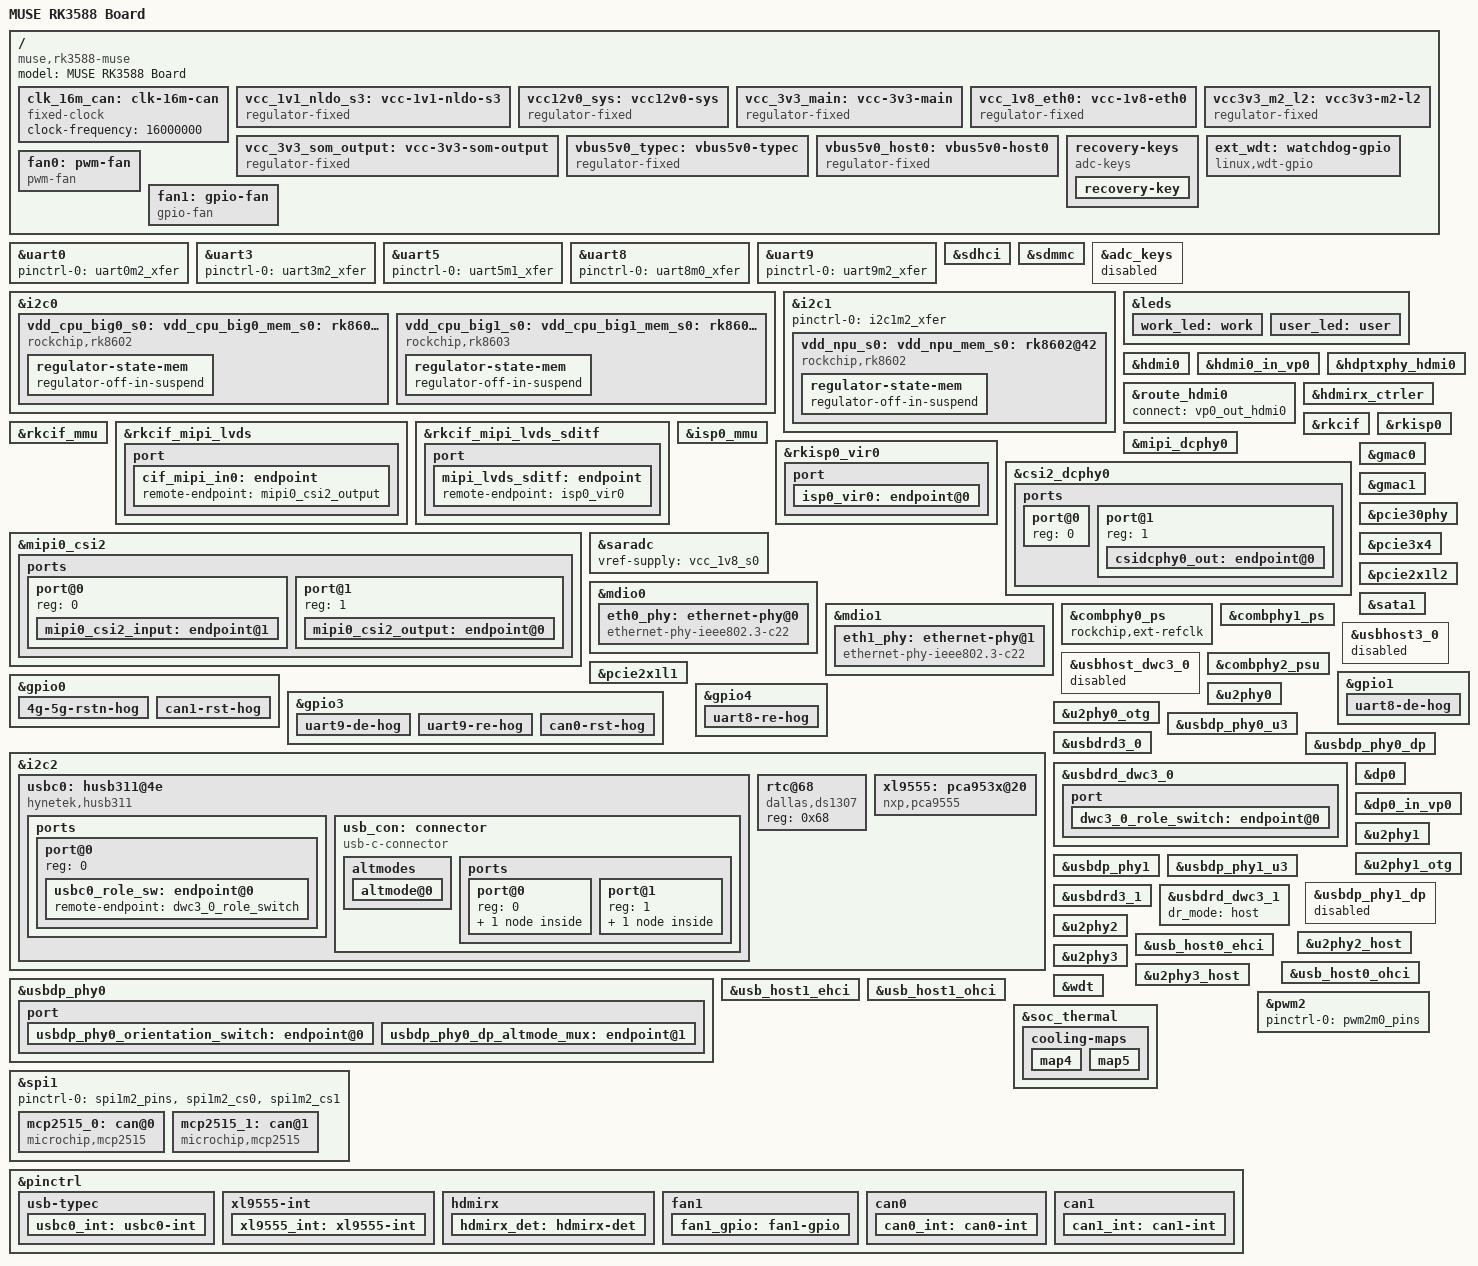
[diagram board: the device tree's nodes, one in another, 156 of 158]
// SPDX-License-Identifier: (GPL-2.0+ OR MIT)
/*
 * Copyright (c) 2026 MUSE Group
 *
 * Device Tree for MUSE RK3588 Board
 * - eMMC boot
 * - LPDDR4X
 * - RK806 single PMIC + discrete RK8602/RK8603
 *
 * Discrete rails (confirmed):
 *   RK8602: VDD_CPU_BIG0, VDD_NPU
 *   RK8603: VDD_CPU_BIG1
 *
 * NOTE: I2C bus / pinmux for RK860x verified against core-board schematic:
 *   I2C0 M2: U2200=RK860-2 @0x42 (VDD_CPU_BIG0), U2201=RK860-3 @0x43 (VDD_CPU_BIG1)
 *   I2C1 M2: U2202=RK860-2 @0x42 (VDD_NPU)
 */

/dts-v1/;

#include "rk3588.dtsi"
#include "rk3588-evb.dtsi"
#include "rk3588-rk806-single.dtsi"
#include "rk3588-linux.dtsi"
#include <dt-bindings/usb/pd.h>

/*
 * UART2 debug console: already enabled in rk3588-linux.dtsi.
 * Pinctrl: uart2m0_xfer (M0 mux) — matches schematic UART2_TX/RX_M0.
 * Console: earlycon=uart8250,mmio32,0xfeb50000, FIQ debugger at 1.5Mbaud.
 */

/*
 * UART0 — RS232 serial port (P9 connector, 10-pin IDC header).
 *
 * Hardware path (carrier-board schematic):
 *   SoC UART0_TX_M2 (GPIO4_A3, ball AL29) → R468 (10Ω) → U59 T1IN
 *   U59 R1OUT → R469 (10Ω) → SoC UART0_RX_M2 (GPIO4_A4, ball AL28)
 *   U59 = MAX232A / SIT3232EEUE (3.3V RS232 transceiver, no driver needed)
 *   U59 T1OUT → P9 pin 3 (TXD),  P9 pin 2 (RXD) → U59 R1IN
 *
 * Pinctrl: uart0m2_xfer (M2 mux: TX=GPIO4_A3, RX=GPIO4_A4).
 *
 * Note: U66/U67 (also SIT3232EEUE) connect to the GOWIN FPGA (GW5AT676),
 * not directly to the SoC.  Their enablement depends on FPGA firmware.
 */
&uart0 {
	pinctrl-0 = <&uart0m2_xfer>;
	status = "okay";
};

/*
 * UART3 M2 — RS485 channel 1 (J23 connector, carrier-board schematic)
 *
 * Hardware path:
 *   SoC UART3_TX_M2 (GPIO4_A5, ball AK27) → R316 → U27 DI
 *   U27 RO → R307 → SoC UART3_RX_M2 (GPIO4_A6, ball AL27)
 *   U27 = SIT3485E (3.3V RS485 transceiver)
 *     A/B → R309/R306 → J23 pin 11 (TX0) / pin 9 (RX0)
 *
 * Direction control: hardware auto-direction via Q35 NPN transistor.
 *   Q35 base driven by UART3_TX through R319.
 *   When TX idle (high): Q35 on → DE/RE low → receive mode.
 *   When TX active (low): Q35 off → DE/RE pulled high by R304 → transmit mode.
 *   No GPIO needed for RS485 direction control.
 *
 * Pinctrl: uart3m2_xfer (M2 mux: TX=GPIO4_A5, RX=GPIO4_A6).
 * Connector: J23 (KF2EDGR-3.81-2×6P, 12-pin 3.81mm terminal block).
 */
&uart3 {
	pinctrl-0 = <&uart3m2_xfer>;
	status = "okay";
};

/*
 * UART5 M1 — RS485 channel 2 (J23 connector, carrier-board schematic)
 *
 * Hardware path:
 *   SoC UART5_TX_M1 (GPIO3_C4, ball AH26) → R338 → U31 DI
 *   U31 RO → R332 → SoC UART5_RX_M1 (GPIO3_C5, ball AH25)
 *   U31 = SIT3485E (3.3V RS485 transceiver)
 *     A/B → R335/R334 → J23 pin 12 (TX1) / pin 10 (RX1)
 *
 * Direction control: hardware auto-direction via Q36 NPN transistor.
 *   Q36 base driven by UART5_TX through R340.
 *   When TX idle (high): Q36 on → DE/RE low → receive mode.
 *   When TX active (low): Q36 off → DE/RE pulled high by R331 → transmit mode.
 *   No GPIO needed for RS485 direction control.
 *
 * Pinctrl: uart5m1_xfer (M1 mux: TX=GPIO3_C4, RX=GPIO3_C5).
 * Connector: J23 (KF2EDGR-3.81-2×6P, 12-pin 3.81mm terminal block).
 */
&uart5 {
	pinctrl-0 = <&uart5m1_xfer>;
	status = "okay";
};

/*
 * UART8 M0 — RS422 channel 1 (J24 connector, carrier-board schematic)
 *
 * Hardware path:
 *   SoC UART8_TX_M0 (GPIO4_B0, ball AK26) → R315 → U28 DI (pin 6)
 *   U28 RO (pin 3) → R311 → SoC UART8_RX_M0 (GPIO4_B1, ball AL24)
 *   U28 = CA-IS3086WX (isolated RS485/RS422 transceiver, 3.3V↔5V isolation)
 *     Y/Z (pins 11/12) → R321/R323 → U29 PSM712 ESD → J24 pin 11/12 (TX1+/-)
 *     A/B (pins 14/13) → R326/R328 → U30 PSM712 ESD → J24 pin 9/10 (RX1+/-)
 *
 * Direction control (RS422 full-duplex, always enabled):
 *   DE  (pin 5) ← GPIO1_A7 (ball C25)  — gpio-hog output-high
 *   /RE (pin 4) ← GPIO4_B2 (ball AK25) — gpio-hog output-low
 *
 * Pinctrl: uart8m0_xfer (M0 mux: TX=GPIO4_B0, RX=GPIO4_B1).
 * Connector: J24 (KF2EDGR-3.81-2×6P, 12-pin 3.81mm terminal block, pins 9-12).
 */
&uart8 {
	pinctrl-0 = <&uart8m0_xfer>;
	status = "okay";
};

/*
 * UART9 M2 — RS422 channel 2 (J24 connector, carrier-board schematic)
 *
 * Hardware path:
 *   SoC UART9_TX_M2 (GPIO3_D5, ball AB28) → R346 → U32 DI (pin 6)
 *   U32 RO (pin 3) → R343 → SoC UART9_RX_M2 (GPIO3_D4, ball AA27)
 *   U32 = CA-IS3086WX (isolated RS485/RS422 transceiver, 3.3V↔5V isolation)
 *     Y/Z (pins 11/12) → R348/R350 → U33 PSM712 ESD → J24 pin 5/6 (TX2+/-)
 *     A/B (pins 14/13) → R355/R357 → U35 PSM712 ESD → J24 pin 3/4 (RX2+/-)
 *
 * Direction control (RS422 full-duplex, always enabled):
 *   DE  (pin 5) ← GPIO3_D0 (ball AH24) — gpio-hog output-high
 *   /RE (pin 4) ← GPIO3_C7 (ball AJ24) — gpio-hog output-low
 *
 * Pinctrl: uart9m2_xfer (M2 mux: TX=GPIO3_D5, RX=GPIO3_D4).
 * Connector: J24 (KF2EDGR-3.81-2×6P, 12-pin 3.81mm terminal block, pins 3-6).
 */
&uart9 {
	pinctrl-0 = <&uart9m2_xfer>;
	status = "okay";
};

/ {
	model = "MUSE RK3588 Board";
	compatible = "muse,rk3588-muse", "rockchip,rk3588";

	/* 16 MHz crystal for XL2515 CAN controllers (Y7/U34, Y8/U38) */
	clk_16m_can: clk-16m-can {
		compatible = "fixed-clock";
		#clock-cells = <0>;
		clock-frequency = <16000000>;
	};

	/* Required intermediate supply referenced by rk3588-rk806-single.dtsi */
	vcc_1v1_nldo_s3: vcc-1v1-nldo-s3 {
		compatible = "regulator-fixed";
		regulator-name = "vcc_1v1_nldo_s3";
		regulator-always-on;
		regulator-boot-on;
		regulator-min-microvolt = <1100000>;
		regulator-max-microvolt = <1100000>;
		vin-supply = <&vcc5v0_sys>;
	};

	/*
	 * Board power rails referenced by Ethernet (per schematic):
	 *   12V -> EC2232E DCDC -> 3.3V / 1.8V (no enable GPIO).
	 */
	vcc12v0_sys: vcc12v0-sys {
		compatible = "regulator-fixed";
		regulator-name = "vcc12v0_sys";
		regulator-always-on;
		regulator-boot-on;
		regulator-min-microvolt = <12000000>;
		regulator-max-microvolt = <12000000>;
	};

	/* GMAC0/GMAC1 PHY 3.3V (VDD_3V3_MAIN) */
	vcc_3v3_main: vcc-3v3-main {
		compatible = "regulator-fixed";
		regulator-name = "vcc_3v3_main"; /* VDD_3V3_MAIN */
		regulator-always-on;
		regulator-boot-on;
		regulator-min-microvolt = <3300000>;
		regulator-max-microvolt = <3300000>;
		vin-supply = <&vcc12v0_sys>;
	};

	/* GMAC0 RGMII/MDIO IO domain (RK3588 VCCIO3) is 1.8V (VDD_1V8_ETH0).
	 * rk3588 io-domain driver absent in this 5.10 kernel, so VCCIO3 is
	 * hardware-strapped; this rail is documented only. */
	vcc_1v8_eth0: vcc-1v8-eth0 {
		compatible = "regulator-fixed";
		regulator-name = "vcc_1v8_eth0"; /* VDD_1V8_ETH0 -> VCCIO3 */
		regulator-always-on;
		regulator-boot-on;
		regulator-min-microvolt = <1800000>;
		regulator-max-microvolt = <1800000>;
		vin-supply = <&vcc12v0_sys>;
	};

	/* SD card main power (VDD_3V3_SOM_OUTPUT, 3.3V).
	 * Schematic: SDMMC_PWREN (GPIO0_A5, PMUIO1 domain) is PMIC-controlled
	 * (RK806), not a regular GPIO — no load-switch enable GPIO needed.
	 * Power is always-on via PMIC; vmmc-supply references this regulator. */
	vcc_3v3_som_output: vcc-3v3-som-output {
		compatible = "regulator-fixed";
		regulator-name = "vcc_3v3_som_output"; /* VDD_3V3_SOM_OUTPUT */
		regulator-always-on;
		regulator-boot-on;
		regulator-min-microvolt = <3300000>;
		regulator-max-microvolt = <3300000>;
		vin-supply = <&vcc_3v3_main>;
	};

	/*
	 * M.2 l2 modem 3.3V power (FULL_CARD_POWER_OFF#).
	 *
	 * Schematic: GPIO0_C6 (KEYB_PWROFFn) is a SoC output (1.8V) that
	 * goes through a level shifter (Q21, CJ3400 NPN) on the carrier
	 * board to become a 3.3V signal, which then drives the
	 * FULL_CARD_POWER_OFF# pin on the M.2 connector (CON1).
	 *
	 * Signal path:
	 *   GPIO0_C6 (1.8V) → Q21 level shifter → FULL_CARD_POWER_OFF# (3.3V)
	 *
	 * Polarity: GPIO_ACTIVE_HIGH
	 *   - GPIO0_C6 = HIGH → FULL_CARD_POWER_OFF# = HIGH → modem power ON
	 *   - GPIO0_C6 = LOW  → FULL_CARD_POWER_OFF# = LOW  → modem power OFF
	 *
	 * NOTE: Despite the signal name "KEYB_PWROFFn", GPIO0_C6 is NOT a
	 *       power key. The actual power button is PMIC_PWRONN, which is
	 *       handled by the Rockchip PMIC driver (rk8xx) internally.
	 *
	 * Modem reset is separately controlled via:
	 *   - PERST#  (GPIO4_A2, pcie2x1l1 reset-gpios)
	 *   - 4G_5G_RSTn (GPIO0_B2, gpio-hog)
	 */
	vcc3v3_m2_l2: vcc3v3-m2-l2 {
		compatible = "regulator-fixed";
		regulator-name = "vcc3v3_m2_l2";
		regulator-min-microvolt = <3300000>;
		regulator-max-microvolt = <3300000>;
		enable-gpios = <&gpio0 RK_PC6 GPIO_ACTIVE_HIGH>;
		regulator-boot-on;
		vin-supply = <&vcc_3v3_main>;
	};

	/*
	 * Type-C0 VBUS 5V — controlled by USB_OTG_PWREN = GPIO1_B0.
	 *
	 * Hardware: WS4612 load-switch, GPIO1_B0 high = VBUS on.
	 * Used by HUSB311 Type-C PD controller for VBUS source/sink switching.
	 */
	vbus5v0_typec: vbus5v0-typec {
		compatible = "regulator-fixed";
		regulator-name = "vbus5v0_typec";
		regulator-min-microvolt = <5000000>;
		regulator-max-microvolt = <5000000>;
		enable-active-high;
		gpio = <&gpio1 RK_PB0 GPIO_ACTIVE_HIGH>;
		vin-supply = <&vcc5v0_sys>;
	};

	/*
	 * USB2 Host0 ETH power — for SR9900AI USB-Ethernet.
	 *
	 * Hardware (from carrier-board schematic, page "USB ETH"):
	 *   ETH_PWRON = GPIO2_C4_d (1.8V) → U18 (TXS0108E level shifter)
	 *   → R401 (0Ω) → Q49 GATE (CJ3401 P-ch MOSFET)
	 *   Q49 SOURCE ← VDD_3V3_MAIN (3.3V always-on)
	 *   Q49 DRAIN → FB17 (DNP ferrite) → SR9900AI VDD5
	 *
	 * Polarity: active-LOW (P-ch MOSFET)
	 *   GPIO LOW  → MOSFET ON  → SR9900 powered  → Ethernet up
	 *   GPIO HIGH → MOSFET OFF → SR9900 unpowered → Ethernet down
	 *
	 * Default (GPIO unconfigured): U18 internal pull-up → HIGH → OFF (safe).
	 *
	 * NOTE: "enable-active-high" must NOT be present.  The kernel
	 *   (gpiolib-of.c) uses the presence/absence of that property as the
	 *   SOLE polarity control for regulator-fixed; phandle GPIO_ACTIVE_HIGH
	 *   flags are explicitly ignored.  With enable-active-high the GPIO is
	 *   driven HIGH → MOSFET stays OFF → SR9900 never powers on.
	 *
	 * GPIO2_C4_d is also wired to SATA DEVSLP via R76 (DNP_0Ω), which
	 * breaks that path — so the GPIO is exclusively used for ETH_PWRON.
	 *
	 * regulator-boot-on is essential: the regulator subsystem initialises
	 * (subsys_initcall) before the USB host controller, so power is applied
	 * before USB scans and finds the SR9900AI already powered.
	 */
	vbus5v0_host0: vbus5v0-host0 {
		compatible = "regulator-fixed";
		regulator-name = "vbus5v0_host0";
		regulator-min-microvolt = <3300000>;
		regulator-max-microvolt = <3300000>;
		gpio = <&gpio2 RK_PC4 GPIO_ACTIVE_HIGH>;
		regulator-always-on;
		regulator-boot-on;
		vin-supply = <&vcc_3v3_main>;
	};
};

/*
 * eMMC boot device (on-board BGA eMMC, U4000: INAND_EMMC_153_2L_BGA153).
 *
 * Hardware (from core-board ARM netlist):
 *   - 8-bit data bus: EMMC_D0–D7 → SoC GPIO2_D0–D7 (balls Y33/W33/V32/AA33/
 *     Y32/AA32/W32/V33), via 0Ω series resistors R1309–R1316
 *   - EMMC_CMD  → SoC GPIO2_A0 (ball W34), via R1315 (0Ω)
 *   - EMMC_CLK  → SoC GPIO2_A1 (ball V34), via R1310 (0Ω)
 *   - EMMC_DS   → SoC GPIO2_A2 (ball Y34), via R4003 (0Ω) — HS400 data strobe
 *   - EMMC_RSTn → SoC GPIO2_A3 (ball AA34), via R1312 (0Ω) — driven by SoC
 *     (10K pull-up R4002 to VCC_1V8, decoupling C4009)
 *   - VCC  = VCC_3V3 (3.3V, pins E6/F5/J10/K9)
 *   - VCCQ = VCC_1V8 (1.8V fixed, pins P5/C6/M4/N4/P3) — enables HS400/HS400ES
 *   - Pull-ups: R4000 (10K on D0), R4001 (10K on CMD) to VCC_1V8
 *     (R4004 47K to GND on DS is DNP — not populated)
 *
 * Pinmux: handled by rk3588s-pinctrl.dtsi emmc_bus8 / emmc_clk /
 * emmc_cmd / emmc_data_strobe (mux 1, no board override needed).
 * The Rockchip DWMSHC driver auto-negotiates HS400ES / HS400 / HS200.
 * No board-specific properties needed beyond status = "okay".
 *
 * NOTE: eMMC shares 6 SoC balls (GPIO2_A0/D0–D3/D6) with the on-board SPI
 * NAND Flash (U4300, FSPI M0 mux 2).  Only one controller can be active at
 * a time.  This board boots from eMMC; the SFC controller remains disabled.
 * See the SPI NAND Flash section below for details.
 */
&sdhci {
	status = "okay";
};

/*
 * SPI NAND Flash (U4300: WSON8, 1.8V) — shares FSPI M0 pins with eMMC.
 *
 * Hardware (from core-board ARM netlist):
 *   - FSPI_CLK  → SoC GPIO2_A0 (ball W34), via R1304 (0Ω) — shared w/ EMMC_CMD
 *   - FSPI_CS0  → SoC GPIO2_D6 (ball W32), via R1307 (0Ω) — shared w/ EMMC_D6
 *   - FSPI_D0   → SoC GPIO2_D0 (ball Y33), via R1300 (0Ω) — shared w/ EMMC_D0
 *   - FSPI_D1   → SoC GPIO2_D1 (ball W33), via R1301 (0Ω) — shared w/ EMMC_D1
 *   - FSPI_D2   → SoC GPIO2_D2 (ball V32), via R1302 (0Ω) — shared w/ EMMC_D2
 *   - FSPI_D3   → SoC GPIO2_D3 (ball AA33), via R1303 (0Ω) — shared w/ EMMC_D3
 *   - VCC = VCC_1V8 (pin 8, 1.8V)
 *   - Pull-ups: R4300 (10K on FSPI_D2), R4301 (10K on FSPI_D3) to VCC_1V8
 *
 * The SFC controller (rockchip,sfc @ 0xfe2b0000) uses FSPI M0 pins (mux 2).
 * Since eMMC (mux 1) is the active boot device, SFC must stay disabled to
 * avoid pin conflict.  To boot from SPI NAND instead, disable &sdhci and
 * enable &sfc with pinctrl fspim0_pins + a flash@0 child node.
 */

/*
 * MicroSD card slot (carrier board).
 *
 * Hardware (from schematic):
 *   - 4-bit data bus: SDMMC_D0–D3 (GPIO4_PD0–PD3)
 *   - SDMMC_CMD (GPIO4_PD4), SDMMC_CLK (GPIO4_PD5)
 *   - Card detect: SDMMC_DET = GPIO0_A4 (native CD, active-low)
 *   - SDMMC_PWREN = GPIO0_A5 (PMUIO1 domain, PMIC-controlled — not a GPIO)
 *   - VCC (vmmc):  VDD_3V3_SOM_OUTPUT (3.3V, always-on via PMIC)
 *   - VCCIO (vqmmc): VCCIO2 = VCC_3V3 = VDD_3V3_MAIN (3.3V, fixed)
 *
 * Limitations:
 *   - no-1-8-v: VCCIO2 is fixed at 3.3V (VCC_3V3). Although the hardware
 *     has a VCCIO2_1V8 (VCC_1V8) alternative, the rk3588 io-domain driver
 *     is absent in this 5.10 kernel, so UHS modes (SDR50/104) are
 *     unavailable; max speed is SDR25 / HS @ 50 MHz.
 *   - No write-protect pin on this slot (confirmed in schematic).
 *
 * Pinmux: sdmmc_clk / sdmmc_cmd / sdmmc_det / sdmmc_bus4 (from SoC dtsi
 * default — override is redundant but kept for explicitness).
 */
&sdmmc {
	status = "okay";
	bus-width = <4>;
	cap-sd-highspeed;
	no-1-8-v;
	pinctrl-names = "default";
	pinctrl-0 = <&sdmmc_clk &sdmmc_cmd &sdmmc_det &sdmmc_bus4>;
	vmmc-supply = <&vcc_3v3_som_output>; /* VDD_3V3_SOM_OUTPUT */
	vqmmc-supply = <&vcc_3v3_main>;       /* VCCIO2 = VCC_3V3, fixed 3.3V */
};

/*
 * Disable EVB-only nodes inherited from rk3588-evb.dtsi.
 * adc_keys: EVB uses SARADC for volume keys; our board uses a dedicated
 * recovery-key node instead (see below).
 *
 * Note: es8388 / es8388_sound live in board-specific EVB dtsi
 * (e.g. rk3588-evb1-lp4.dtsi), not in rk3588-evb.dtsi, so do not
 * reference those labels here.
 */
&adc_keys {
	status = "disabled";
};

/*
 * I2C0 — CPU/NPU core-voltage regulators (M2 mux).
 *
 * Bus topology (from core-board schematic):
 *   I2C0_SCL_M2 / I2C0_SDA_M2  →  two discrete DCDC regulators:
 *     U2200 = RK860-2  @ 0x42  →  VDD_CPU_BIG0  (550 mV – 1.05 V)
 *     U2201 = RK860-3  @ 0x43  →  VDD_CPU_BIG1  (550 mV – 1.05 V)
 *   (U2202 = RK860-2 for VDD_NPU is on a separate I2C1 bus — see &i2c1 below.)
 *
 * Also on this bus: GW5A FPGA @ 0x51 ( PCIe endpoint).
 * Clock: 100 kHz standard mode (FPGA + regulators share the bus).
 *
 * Pinmux: i2c0m2_xfer (M2 mux: SCL=GPIO0_D1, SDA=GPIO0_D2).
 */
&i2c0 {
	status = "okay";
	clock-frequency = <100000>; /* FPGA (GW5A @0x51) + RK860x share this bus; 100kHz standard mode */
	pinctrl-names = "default";
	pinctrl-0 = <&i2c0m2_xfer>;

	vdd_cpu_big0_s0: vdd_cpu_big0_mem_s0: rk8602@42 {
		compatible = "rockchip,rk8602";
		reg = <0x42>;
		vin-supply = <&vcc5v0_sys>;
		regulator-compatible = "rk860x-reg";
		regulator-name = "vdd_cpu_big0_s0";
		regulator-min-microvolt = <550000>;
		regulator-max-microvolt = <1050000>;
		regulator-ramp-delay = <2300>;
		rockchip,suspend-voltage-selector = <1>;
		regulator-boot-on;
		regulator-always-on;
		regulator-state-mem {
			regulator-off-in-suspend;
		};
	};

	vdd_cpu_big1_s0: vdd_cpu_big1_mem_s0: rk8603@43 {
		compatible = "rockchip,rk8603";
		reg = <0x43>;
		vin-supply = <&vcc5v0_sys>;
		regulator-compatible = "rk860x-reg";
		regulator-name = "vdd_cpu_big1_s0";
		regulator-min-microvolt = <550000>;
		regulator-max-microvolt = <1050000>;
		regulator-ramp-delay = <2300>;
		rockchip,suspend-voltage-selector = <1>;
		regulator-boot-on;
		regulator-always-on;
		regulator-state-mem {
			regulator-off-in-suspend;
		};
	};
};

/*
 * I2C1 — NPU core-voltage regulator (M2 mux).
 *
 * Bus topology (from core-board schematic):
 *   I2C1_SCL_M2 / I2C1_SDA_M2  →  one discrete DCDC regulator:
 *     U2202 = RK860-2  @ 0x42  →  VDD_NPU  (550 mV – 0.95 V)
 *
 * Pinmux: i2c1m2_xfer (M2 mux: SCL=GPIO0_D4, SDA=GPIO0_D5).
 * Clock: 100 kHz (default).
 */
&i2c1 {
	status = "okay";
	pinctrl-names = "default";
	pinctrl-0 = <&i2c1m2_xfer>;

	vdd_npu_s0: vdd_npu_mem_s0: rk8602@42 {
		compatible = "rockchip,rk8602";
		reg = <0x42>;
		vin-supply = <&vcc5v0_sys>;
		regulator-compatible = "rk860x-reg";
		regulator-name = "vdd_npu_s0";
		regulator-min-microvolt = <550000>;
		regulator-max-microvolt = <950000>;
		regulator-ramp-delay = <2300>;
		rockchip,suspend-voltage-selector = <1>;
		regulator-boot-on;
		regulator-always-on;
		regulator-state-mem {
			regulator-off-in-suspend;
		};
	};
};

/*
 * GPIO LEDs (D1 / D2 on carrier board).
 *
 * Hardware (from core-board schematic):
 *   - D1 (LED1) = GPIO0_C5  →  green, heartbeat trigger
 *   - D2 (LED2) = GPIO0_D3  →  green, default-on (power indicator)
 *   - Both active-high (GPIO high → LED on)
 *
 * Overrides the EVB &leds node (which uses GPIO3_B7).
 */
&leds {
	work_led: work {
		gpios = <&gpio0 RK_PC5 GPIO_ACTIVE_HIGH>;
		linux,default-trigger = "heartbeat";
	};

	user_led: user {
		gpios = <&gpio0 RK_PD3 GPIO_ACTIVE_HIGH>;
		default-state = "on";
	};
};

/*
 * HDMI0 output: VOP0 (VP0) → HDMI0 TX → HDMI connector.
 *
 * Hardware (from carrier-board schematic, all M0 mux):
 *   - HDMI_TX0_SCL_M0  = GPIO4_B7  (DDC I2C clock)
 *   - HDMI_TX0_SDA_M0  = GPIO4_C0  (DDC I2C data)
 *   - HDMI_TX0_HPD_M0  = GPIO1_A5  (hot-plug detect)
 *   - HDMI_TX0_CEC_M0  = GPIO4_C1  (repurposed as HDMI0_TX_ON_H power control)
 *   - Differential pairs: TX0P/N – TX3P/N (4 lanes)
 *
 * GPIO4_C1 (AK24) is used as HDMI0_TX_ON_H (GPIO output for HDMI TX power
 * enable), not as CEC.  CEC is therefore omitted from the pinctrl.
 *
 * PHY: &hdptxphy_hdmi0 (on-chip HDMI PHY, enabled below).
 * Route: VP0 → HDMI0 (no intermediate split).
 */
&hdmi0 {
	status = "okay";
	pinctrl-0 = <&hdmim0_tx0_hpd &hdmim0_tx0_scl &hdmim0_tx0_sda>;
};

&hdmi0_in_vp0 {
	status = "okay";
};

&hdptxphy_hdmi0 {
	status = "okay";
};

&route_hdmi0 {
	status = "okay";
	connect = <&vp0_out_hdmi0>;
};

/*
 * HDMI RX (HDMI IN) — carrier-board HDMI Type-A input connector.
 *
 * Hardware (from carrier-board schematic):
 *   - HDMI RX signals use M2 pinmux:
 *       HPD  = GPIO1_B6 (hdmim2_rx_hpdin)
 *       SCL  = GPIO1_D6 (hdmim2_rx_scl)
 *       SDA  = GPIO1_D7 (hdmim2_rx_sda)
 *   - CEC (GPIO1_B7, hdmim2_rx_cec) is not connected on this board — omitted.
 *   - 5V detect = GPIO4_A1, active-low (HDMI_RX_DET_L)
 *
 * Driver: CONFIG_VIDEO_ROCKCHIP_HDMIRX=y (rk_hdmirx.c)
 * CMA: uses default 8 MB CMA from rk3588-linux.dtsi (no dedicated reserved memory).
 */
&hdmirx_ctrler {
	status = "okay";

	#sound-dai-cells = <1>;
	/* Effective level used to trigger HPD: 0-low, 1-high */
	hpd-trigger-level = <1>;
	hdmirx-det-gpios = <&gpio4 RK_PA1 GPIO_ACTIVE_LOW>;
	pinctrl-names = "default";
	pinctrl-0 = <&hdmim2_rx_hpdin &hdmim2_rx_scl &hdmim2_rx_sda &hdmirx_det>;
};

/*
 * MIPI CSI — carrier-board camera connectors.
 *
 * Hardware (from carrier-board schematic):
 *   - CSI0: 4-lane (D0-D3, CLK0, CLK1) → 30-pin FPC connector
 *   - CSI1: 4-lane (D0-D3, CLK0, CLK1) → 2× FFC connectors
 *   - PWDN1-4 controlled by XL9555 I/O expander (P02-P05)
 *
 * The base camera pipeline (RKCIF → CSI host → DPHY) is enabled below.
 * A camera sensor node (e.g., imx415@1a) with its I2C bus, power GPIOs,
 * and endpoint linking sensor→DPHY must be added for each connected sensor.
 *
 * Pipeline: sensor → csi2_dcphy0 → mipi0_csi2 → rkcif_mipi_lvds → rkcif
 *                    → rkcif_mipi_lvds_sditf → rkisp0_vir0 → rkisp0
 *
 * Board design: the MIPI CSI connector (J19) has a MIPI_MCLK pin but it is
 * NOT routed to any SoC camera clock output GPIO (CLK_MIPI_CAMARAOUT).
 * The camera sensor must use its own oscillator.  No camera clock GPIO is
 * needed, so there is NO pin conflict with HDMI RX M2 (GPIO1_B6/D6/D7).
 * Power domains are separate (HDMI RX=PD_VO1, CSI=PD_VI).
 */
&rkcif {
	status = "okay";
};

&rkcif_mmu {
	status = "okay";
};

&rkcif_mipi_lvds {
	status = "okay";

	port {
		cif_mipi_in0: endpoint {
			remote-endpoint = <&mipi0_csi2_output>;
		};
	};
};

&rkcif_mipi_lvds_sditf {
	status = "okay";

	port {
		mipi_lvds_sditf: endpoint {
			remote-endpoint = <&isp0_vir0>;
		};
	};
};

&rkisp0 {
	status = "okay";
};

&isp0_mmu {
	status = "okay";
};

&rkisp0_vir0 {
	status = "okay";

	port {
		#address-cells = <1>;
		#size-cells = <0>;

		isp0_vir0: endpoint@0 {
			reg = <0>;
			remote-endpoint = <&mipi_lvds_sditf>;
		};
	};
};

&mipi_dcphy0 {
	status = "okay";
};

&csi2_dcphy0 {
	status = "okay";

	ports {
		#address-cells = <1>;
		#size-cells = <0>;
		port@0 {
			reg = <0>;
			#address-cells = <1>;
			#size-cells = <0>;

			/*
			 * Sensor input endpoints — add when a camera is connected:
			 *   mipi_in_ucam0: endpoint@1 {
			 *       reg = <1>;
			 *       remote-endpoint = <&sensor_out0>;
			 *       data-lanes = <1 2 3 4>;
			 *   };
			 */
		};
		port@1 {
			reg = <1>;
			#address-cells = <1>;
			#size-cells = <0>;

			csidcphy0_out: endpoint@0 {
				reg = <0>;
				remote-endpoint = <&mipi0_csi2_input>;
			};
		};
	};
};

&mipi0_csi2 {
	status = "okay";

	ports {
		#address-cells = <1>;
		#size-cells = <0>;

		port@0 {
			reg = <0>;
			#address-cells = <1>;
			#size-cells = <0>;

			mipi0_csi2_input: endpoint@1 {
				reg = <1>;
				remote-endpoint = <&csidcphy0_out>;
			};
		};

		port@1 {
			reg = <1>;
			#address-cells = <1>;
			#size-cells = <0>;

			mipi0_csi2_output: endpoint@0 {
				reg = <0>;
				remote-endpoint = <&cif_mipi_in0>;
			};
		};
	};
};

/*
 * SAR ADC — 8-channel, 12-bit, 1.8 V reference (from RK806 PLDO_REG2).
 *
 * Channel mapping (from core-board schematic):
 *   IN0: SARADC_IN0_BOOT  — boot mode selection (read by bootloader)
 *   IN1: SARADC_IN1       — RECOVERY_KEY (adc-keys: pressed≈0 V, released≈1.8 V)
 *   IN2: SARADC_IN2       — reserved (routed to connector)
 *   IN3: SARADC_IN3       — reserved (routed to connector)
 *   IN4: SARADC_IN4       — reserved (routed to connector)
 *   IN5: SARADC_VIN5_HW_ID — HW_ID (hardware revision identification, IIO sysfs)
 *
 * The recovery key on IN1 is configured as an adc-keys node below.
 * HW_ID on IN5 is read from user space via IIO sysfs — no DTS node needed.
 */
&saradc {
	status = "okay";
	vref-supply = <&vcc_1v8_s0>;
};

/*
 * Recovery key on SARADC channel 1 (SARADC_IN1).
 *
 * Hardware: momentary push-button (KEY1) on carrier board.
 *   - Pressed:  ADC reads ≈ 0 V (button shorts to GND)
 *   - Released: ADC reads ≈ 1.8 V (pull-up to vref)
 *   - Threshold: < 100 mV = pressed
 *
 * Generates KEY_VOLUMEDOWN for Android recovery boot trigger.
 * (In pure Linux without a recovery daemon, this node can be removed.)
 */
/ {
	recovery-keys {
		compatible = "adc-keys";
		io-channels = <&saradc 1>;
		io-channel-names = "buttons";
		keyup-threshold-microvolt = <1800000>;
		poll-interval = <100>;

		recovery-key {
			label = "recovery";
			linux,code = <KEY_VOLUMEDOWN>;
			press-threshold-microvolt = <100000>;
		};
	};
};

/*
 * GMAC0 → YT8531SH-CA (U6) RGMII PHY, MDIO address 0.
 *
 * Hardware (from carrier-board schematic):
 *   - RGMII: TX_CLK/RX_CLK, TXD0–3, RXD0–3, TX_CTL, RX_CTL
 *   - MDIO:  MDC, MDIO  (mdio0 bus)
 *   - RESET: ETH0_RSTn = GPIO3_B2 (active-low)
 *   - Clock: PHY has onboard 25 MHz crystal → supplies 125 MHz ref clk
 *            to SoC  ⇒  clock_in_out = "input"
 *   - IO voltage: VCCIO3 = 1.8 V (VDD_1V8_ETH0)
 *   - PHY address: 0 (PHYAD0 pin reused as LED0 output)
 *
 * PHY driver: motorcomm (YT8531S), matched by PHY ID 0x4f51e91a
 *              (auto-detected at runtime; "SH" = S variant + QFN package).
 * RGMII delay: PHY provides RX delay (2 ns via pull-up on RXD0);
 *              SoC provides TX delay via tx_delay register.
 *              ⇒ phy-mode = "rgmii-rxid".
 *
 * TODO: calibrate tx_delay on real hardware with iperf / ethtool.
 */
&gmac0 {
	phy-mode = "rgmii-rxid"; /* RX delay provided by PHY; TX delay set below */
	clock_in_out = "input"; /* driver selects external PHY clock via GRF/CRU */

	/* RGMII IO is VCCIO3 1.8V */
	snps,reset-gpio = <&gpio3 RK_PB2 GPIO_ACTIVE_LOW>;
	snps,reset-active-low;
	/* YT8531S reset low pulse; 20ms exceeds datasheet t_RST(min). Tune down if needed */
	snps,reset-delays-us = <0 20000 100000>;

	/* TODO: calibrate tx_delay on real board with iperf/ethtool */
	tx_delay = <0x30>;

	pinctrl-names = "default";
	pinctrl-0 = <&gmac0_miim
		     &gmac0_tx_bus2
		     &gmac0_rx_bus2
		     &gmac0_rgmii_clk
		     &gmac0_rgmii_bus>;

	phy-handle = <&eth0_phy>;
	status = "okay";
};

&mdio0 {
	eth0_phy: ethernet-phy@0 {
		/* YT8531S matched by PHY ID 0x4f51e91a via motorcomm driver */
		compatible = "ethernet-phy-ieee802.3-c22";
		reg = <0x0>;
		/* RGMII IO is 1.8V (VCCIO3) -> matches SoC side IO voltage */
		motorcomm,vddio = "1v8";
		/* YT8531S: no TXDLY on chip; RXDLY enabled by pull-up on RXD0
		 * (2ns @125MHz). So rgmii-rxid is correct: SoC adds TX delay via
		 * tx_delay, PHY adds RX delay. motorcomm,vddio is documentation-
		 * only for YT8531S (driver reads it only for YT8011). VCCIO3
		 * = 1.8V is hardware-strapped. tx_delay needs calibration. */
	};
};

/*
 * GMAC1 → YT8531SH-CA (U9) RGMII PHY, MDIO address 1.
 *
 * Hardware (from carrier-board schematic):
 *   - RGMII: TX_CLK/RX_CLK, TXD0–3, RXD0–3, TX_CTL, RX_CTL
 *   - MDIO:  MDC, MDIO  (mdio1 bus)
 *   - RESET: ETH1_RSTn = GPIO3_B6 (active-low)
 *   - Clock: PHY has onboard 25 MHz crystal → supplies 125 MHz ref clk
 *            to SoC  ⇒  clock_in_out = "input"
 *   - IO voltage: 3.3 V domain
 *   - PHY address: 1 (PHYAD0 pin strapped high)
 *
 * PHY driver: motorcomm (YT8531S), matched by PHY ID 0x4f51e91a
 *              (auto-detected at runtime; "SH" = S variant + QFN package).
 * RGMII delay: same scheme as GMAC0 — PHY RX delay, SoC TX delay.
 *
 * TODO: calibrate tx_delay on real hardware with iperf / ethtool.
 */
&gmac1 {
	phy-mode = "rgmii-rxid";
	clock_in_out = "input";

	/* RGMII IO is 3.3V domain */
	snps,reset-gpio = <&gpio3 RK_PB6 GPIO_ACTIVE_LOW>;
	snps,reset-active-low;
	/* 20ms reset pulse exceeds YT8531S t_RST(min); tune down if needed */
	snps,reset-delays-us = <0 20000 100000>;

	tx_delay = <0x30>; /* TODO: calibrate on real board */

	pinctrl-names = "default";
	pinctrl-0 = <&gmac1_miim
		     &gmac1_tx_bus2
		     &gmac1_rx_bus2
		     &gmac1_rgmii_clk
		     &gmac1_rgmii_bus>;

	phy-handle = <&eth1_phy>;
	status = "okay";
};

&mdio1 {
	eth1_phy: ethernet-phy@1 {
		compatible = "ethernet-phy-ieee802.3-c22"; /* YT8531S, PHY ID 0x4f51e91a */
		reg = <0x1>;
		motorcomm,vddio = "3v3"; /* RGMII IO is 3.3V */
		/* YT8531S: no TXDLY on chip; RXDLY enabled by pull-up on RXD0
		 * (2ns @125MHz). rgmii-rxid correct: SoC adds TX delay.
		 * motorcomm,vddio is documentation-only for YT8531S (driver
		 * reads it only for YT8011). VCCIO4 = 3.3V is hardware-strapped.
		 * tx_delay needs on-board calibration. */
	};
};

/*
 * PCIe 3.0 x4 (pcie3x4) → GW5A FPGA endpoint.
 *
 * Hardware (from core-board schematic):
 *   - Reference clock: external RS2CG5705BLE clock buffer (always-on)
 *     Output 1: PCIE30_PORT0_REF_CLKP/N → RK3588 PCIe3x4 ref clk
 *     Output 2: PCIE30_PORT1_REF_CLKP/N → RK3588 (unused port)
 *     Output 3: Q0_REFCLKP/N            → FPGA ref clk
 *   - FPGA PERST# is not connected to any RK3588 GPIO (no reset-gpios)
 *   - PCIe 3.3V power: fixed/always-on (no vpcie3v3-supply)
 *   - CLKREQ# not used (external clock chip runs independently)
 *
 * PHY: pcie30phy in aggregation mode (x4).
 */
&pcie30phy {
	rockchip,pcie30-phymode = <PHY_MODE_PCIE_AGGREGATION>;
	status = "okay";
};

&pcie3x4 {
	status = "okay";
};

/*
 * PCIe 2.0 x1 lanes + SATA.
 *
 * l2 (pcie2x1l2): mini PCIe slot (C9963).
 *   - Data lanes: PCIE20_0 (via combphy0_ps)
 *   - External ref clock: PI6C557-05BLE (feeds both SoC and connector)
 *   - Reset: SoC NPOR (ball M31) via U19 level shifter (1.8V→3.3V)
 *     NPOR is power-on reset, not a GPIO — no reset-gpios needed
 *   - SMBus (SMCLK/SMDAT) on connector wired to I2C2 (not used by PCIe)
 *   - combphy0_ps in PCIe mode with ext-refclk
 *   - Power: always-on
 *
 * l1 (pcie2x1l1): M.2 B-key 4G/5G modem (RM500Q-GL).
 *   - Data lanes: PCIE20_2 (via combphy2_psu)
 *   - PCIe mode (MHI over PCIe), SoC internal clock
 *   - Reset: GPIO4_A2 (A/AM29, PCIE30X1_1_PERSTN_M1, active-high)
 *     (via R85 0Ω to CON1 PERST# pin 50; R83 to GPIO0_C7 is DNP)
 *   - CLKREQ# / WAKE# not connected
 *   - Power: FULL_CARD_POWER_OFF# controlled by GPIO0_C6 (KEYB_PWROFFn)
 *     via Q21 level shifter, see vcc3v3_m2_l2 regulator above
 *   - Modem RESET#: GPIO0_B2 (4G_5G_RSTn, 1.8V, gpio-hog output-high)
 *   - combphy2_psu in PCIe mode
 *
 * SATA: M.2 B-key SATA SSD (CON4) via combphy1_ps in SATA mode → &sata1.
 *   - Data lanes: SATA30_1 (via combphy1_ps)
 */

/* combphy0_ps: PCIe mode with external refclk for pcie2x1l2 (mini PCIe slot) */
&combphy0_ps {
	rockchip,ext-refclk;
	status = "okay";
};

&pcie2x1l2 {
	status = "okay";
};

/* combphy1_ps: SATA mode for M.2 B-key SATA SSD (CON4) → sata1 */
&combphy1_ps {
	status = "okay";
};

&sata1 {
	status = "okay";
};

/*
 * USB3 Host controller 2 (usbhost3_0 / usbhost_dwc3_0) — DISABLED.
 *
 * usbhost_dwc3_0 requires combphy2_psu in USB3 mode, but combphy2_psu is
 * already in PCIe mode for pcie2x1l1 (M.2 4G/5G modem).  The SoC pins
 * PCIE20_2/SATA30_2/USB30_2 are triplexed — only one function at a time.
 * Schematic confirms no USB3 device on these lanes, so disable to avoid
 * PHY mode conflict with pcie2x1l1.
 */
&usbhost3_0 {
	status = "disabled";
};

&usbhost_dwc3_0 {
	status = "disabled";
};

/* combphy2_psu: PCIe mode for pcie2x1l1 (M.2 4G/5G modem) */
&combphy2_psu {
	status = "okay";
};

/*
 * pcie2x1l1: M.2 B-key 4G/5G modem (RM500Q-GL).
 * Reset: GPIO4_A2 (PCIE30X1_1_PERSTN_M1, active-high in Rockchip convention).
 * Power: vcc3v3_m2_l2 (GPIO0_C6 → level shifter → FULL_CARD_POWER_OFF#).
 */
&pcie2x1l1 {
	reset-gpios = <&gpio4 RK_PA2 GPIO_ACTIVE_HIGH>;
	vpcie3v3-supply = <&vcc3v3_m2_l2>;
	status = "okay";
};

/*
 * Modem control GPIO (RM500Q-GL on PCIe l1):
 *   4G_5G_RSTn = GPIO0_B2 (1.8V, active-high in Rockchip convention).
 *   Hogged high at boot to keep the modem out of reset.
 *   (Toggle low→high to force a modem cold reset if needed.)
 */
&gpio0 {
	4g-5g-rstn-hog {
		gpio-hog;
		gpios = <RK_PB2 GPIO_ACTIVE_HIGH>;
		output-high;
		line-name = "4g_5g_rstn";
	};
};

/*
 * RS422 DE/RE direction-control GPIOs (CA-IS3086WX isolated transceivers).
 *
 * UART8 (U28) RS422 channel 1 — full-duplex, always enabled:
 *   DE  = GPIO1_A7 (ball C25)  → output-high (driver always on)
 *   /RE = GPIO4_B2 (ball AK25) → output-low  (receiver always on)
 *
 * UART9 (U32) RS422 channel 2 — full-duplex, always enabled:
 *   DE  = GPIO3_D0 (ball AH24) → output-high (driver always on)
 *   /RE = GPIO3_C7 (ball AJ24) → output-low  (receiver always on)
 */
&gpio1 {
	uart8-de-hog {
		gpio-hog;
		gpios = <RK_PA7 GPIO_ACTIVE_HIGH>;
		output-high;
		line-name = "uart8_de";
	};
};

&gpio3 {
	uart9-de-hog {
		gpio-hog;
		gpios = <RK_PD0 GPIO_ACTIVE_HIGH>;
		output-high;
		line-name = "uart9_de";
	};
	uart9-re-hog {
		gpio-hog;
		gpios = <RK_PC7 GPIO_ACTIVE_HIGH>;
		output-low;
		line-name = "uart9_re_n";
	};
};

&gpio4 {
	uart8-re-hog {
		gpio-hog;
		gpios = <RK_PB2 GPIO_ACTIVE_HIGH>;
		output-low;
		line-name = "uart8_re_n";
	};
};

/*
 * I2C2 — Type-C0 controller + DS1307 RTC (M0 mux).
 *
 * Bus topology (from carrier-board schematic):
 *   I2C2_SCL_M0 / I2C2_SDA_M0  →  three devices:
 *     U47  = HUSB311  @ 0x4e  (Type-C PD + orientation controller)
 *     U24  = DS1307ZM  @ 0x68  (external RTC, Y4 32.768 kHz crystal + backup battery)
 *     U26  = XL9555    @ 0x20  (16-bit I/O expander: SATA_DEVSLP, MIPI CSI PWDN1-4)
 *
 * Pinmux: i2c2m0_xfer (M0 mux: SCL=GPIO0_B7, SDA=GPIO0_C0).
 * Clock: 400 kHz fast mode.
 */
&i2c2 {
	status = "okay";
	pinctrl-names = "default";
	pinctrl-0 = <&i2c2m0_xfer>;
	clock-frequency = <400000>;

	/*
	 * HUSB311 Type-C PD controller (U47) @ 0x4e.
	 *
	 * Hardware:
	 *   - INT pin = GPIO4_B6 (active-low, pull-up)
	 *   - VBUS 5V via WS4612 load-switch, enabled by USB_OTG_PWREN = GPIO1_B0
	 *   - DP0 alt-mode: SBU1→AUXP, SBU2→AUXN
	 *   - Orientation: DC pins GPIO3_B7 (sbu1) / GPIO3_D1 (sbu2)
	 *
	 * Driver: hynetek,husb311 (Type-C + DP alt-mode mux).
	 */
	usbc0: husb311@4e {
		compatible = "hynetek,husb311";
		reg = <0x4e>;
		interrupt-parent = <&gpio4>;
		interrupts = <RK_PB6 IRQ_TYPE_LEVEL_LOW>;
		pinctrl-names = "default";
		pinctrl-0 = <&usbc0_int>;
		vbus-supply = <&vbus5v0_typec>;
		status = "okay";

		ports {
			#address-cells = <1>;
			#size-cells = <0>;

			port@0 {
				reg = <0>;
				usbc0_role_sw: endpoint@0 {
					remote-endpoint = <&dwc3_0_role_switch>;
				};
			};
		};

		usb_con: connector {
			compatible = "usb-c-connector";
			label = "USB-C";
			data-role = "dual";
			power-role = "dual";
			try-power-role = "sink";
			op-sink-microwatt = <1000000>;
			sink-pdos = <PDO_FIXED(5000, 1000, PDO_FIXED_USB_COMM)>;
			source-pdos = <PDO_FIXED(5000, 3000, PDO_FIXED_USB_COMM)>;

			altmodes {
				#address-cells = <1>;
				#size-cells = <0>;

				altmode@0 {
					reg = <0>;
					svid = <0xff01>;
					vdo = <0xffffffff>;
				};
			};

			ports {
				#address-cells = <1>;
				#size-cells = <0>;

				port@0 {
					reg = <0>;
					usbc0_orien_sw: endpoint {
						remote-endpoint = <&usbdp_phy0_orientation_switch>;
					};
				};

				port@1 {
					reg = <1>;
					dp_altmode_mux: endpoint {
						remote-endpoint = <&usbdp_phy0_dp_altmode_mux>;
					};
				};
			};
		};
	};

	/*
	 * DS1307 RTC (U24) @ 0x68 — external I2C real-time clock.
	 *
	 * Hardware (from carrier-board schematic):
	 *   - Y4 = 32.768 kHz crystal on X1/X2 pins
	 *   - 3 V backup battery (CON11) on VBAT pin
	 *   - SQW/OUT pin unused
	 *   - VCC = 5 V (DS1307ZM); I2C open-drain, pull-ups to SoC IO domain
	 *   - Shares I2C2 M0 bus with HUSB311
	 *
	 * Driver: rtc-ds1307 (dallas,ds1307 compatible).
	 * The SoC internal RK806 RTC also exists; this external RTC provides
	 * time-keeping across power loss when main power is removed.
	 */
	rtc@68 {
		compatible = "dallas,ds1307";
		reg = <0x68>;
		status = "okay";
	};

	/*
	 * XL9555 I/O expander (U26) @ 0x20 — 16-bit GPIO expander.
	 *
	 * Hardware (from carrier-board schematic):
	 *   - I2C2 M0 bus, address 0x20 (A0=A1=A2=GND)
	 *   - INT pin = GPIO4_A0 (active-low, open-drain, pull-up)
	 *   - P00 = SATA_DEVSLP
	 *   - P02 = MIPI_CSI_PWDN1, P03 = MIPI_CSI_PWDN2
	 *   - P04 = MIPI_CSI_PWDN3, P05 = MIPI_CSI_PWDN4
	 *   - P01, P06, P07, P10-P17 unused
	 *
	 * Driver: gpio-pca953x (nxp,pca9555 compatible; XL9555 is pin/function
	 * compatible with NXP PCA9555 — 16-bit I2C GPIO expander with INT output).
	 */
	xl9555: pca953x@20 {
		compatible = "nxp,pca9555";
		reg = <0x20>;
		gpio-controller;
		#gpio-cells = <2>;
		interrupt-parent = <&gpio4>;
		interrupts = <RK_PA0 IRQ_TYPE_EDGE_FALLING>;
		pinctrl-names = "default";
		pinctrl-0 = <&xl9555_int>;
		status = "okay";
	};
};

&u2phy0 {
	status = "okay";
};

&u2phy0_otg {
	status = "okay";
};

/*
 * USB3.0 + DP0 combo PHY (usbdp_phy0) for Type-C0.
 *
 * Hardware:
 *   - Orientation switch enabled (Type-C can be flipped)
 *   - SBU1 DC pin = GPIO3_B7, SBU2 DC pin = GPIO3_D1
 *     (used by HUSB311 to signal cable orientation)
 *   - SVID 0xff01 = DisplayPort alt-mode
 *   - SuperSpeed lanes shared between USB3.0 and DP0
 */
&usbdp_phy0 {
	orientation-switch;
	svid = <0xff01>;
	sbu1-dc-gpios = <&gpio3 RK_PB7 GPIO_ACTIVE_HIGH>;
	sbu2-dc-gpios = <&gpio3 RK_PD1 GPIO_ACTIVE_HIGH>;
	status = "okay";

	port {
		#address-cells = <1>;
		#size-cells = <0>;
		usbdp_phy0_orientation_switch: endpoint@0 {
			reg = <0>;
			remote-endpoint = <&usbc0_orien_sw>;
		};

		usbdp_phy0_dp_altmode_mux: endpoint@1 {
			reg = <1>;
			remote-endpoint = <&dp_altmode_mux>;
		};
	};
};

&usbdp_phy0_u3 {
	status = "okay";
};

&usbdp_phy0_dp {
	status = "okay";
};

&usbdrd3_0 {
	status = "okay";
};

/*
 * USB3.0 DRD controller 0 (dwc3_0) — Type-C0 OTG.
 *
 * Mode: OTG (dual-role: Host or Device, switched by HUSB311 CC logic).
 * USB role switch wired to HUSB311 Type-C controller via endpoint.
 */
&usbdrd_dwc3_0 {
	dr_mode = "otg";
	usb-role-switch;
	status = "okay";
	port {
		#address-cells = <1>;
		#size-cells = <0>;
		dwc3_0_role_switch: endpoint@0 {
			reg = <0>;
			remote-endpoint = <&usbc0_role_sw>;
		};
	};
};

/*
 * DisplayPort 0 (DP0) — alt-mode on Type-C0 USB3.0.
 *
 * Routed through usbdp_phy0; enabled when HUSB311 negotiates DP alt-mode.
 * Source: VOP0 (VP0) → DP0.
 */
&dp0 {
	status = "okay";
};

&dp0_in_vp0 {
	status = "okay";
};

/*
 * USB3_1 Host (Type-C1): USB 3.1 Host-only port.
 *
 * Hardware (from carrier-board schematic):
 *   - No Type-C CC controller (pure Host, no PD negotiation)
 *   - VBUS 5V always-on (WS4612 power switch, EN tied high — no GPIO control)
 *   - USB3.1 SuperSpeed lanes + USB2 D+/D−
 *   - Reset via NPOR_u (PMU power-on reset, auto-release — no GPIO)
 *
 * Controller: usbdrd3_1 / usbdrd_dwc3_1 in Host mode.
 * PHY: u2phy1 + usbdp_phy1 (no orientation switch needed — Host only).
 */
&u2phy1 {
	status = "okay";
};

&u2phy1_otg {
	status = "okay";
};

&usbdp_phy1 {
	status = "okay";
};

&usbdp_phy1_u3 {
	status = "okay";
};

/* Type-C1 has no PD controller → no DP alt-mode negotiation → disable DP */
&usbdp_phy1_dp {
	status = "disabled";
};

&usbdrd3_1 {
	status = "okay";
};

/*
 * USB3.1 DRD controller 1 (dwc3_1) — Type-C1 Host-only.
 *
 * Mode: Host (no OTG — no CC controller on this port).
 */
&usbdrd_dwc3_1 {
	dr_mode = "host";
	status = "okay";
};

/*
 * USB2 Host0: SR9900AI USB-to-Ethernet adapter (ETH2).
 *
 * Hardware (from carrier-board schematic, page "USB ETH"):
 *   - SR9900AI is a USB 2.0 → 10/100 Ethernet chip (U42)
 *   - Power: 3.3V via P-ch MOSFET Q49, controlled by ETH_PWRON = GPIO2_C4_d
 *   - Polarity: active-LOW (GPIO low = MOSFET on = SR9900 powered)
 *   - USB2 D+/D− only (no SuperSpeed)
 *
 * The SR9900AI is a standard USB Ethernet device; it auto-enumerates
 * once the USB host controller is active.  No board-specific DTS node
 * is needed for the device itself — only the host controller + PHY.
 * Power is kept always-on (regulator-always-on + regulator-boot-on)
 * since the SR9900AI has no software shutdown pin; the MOSFET is the
 * only power-gating mechanism.
 */
&u2phy2 {
	status = "okay";
};

&u2phy2_host {
	status = "okay";
};

&usb_host0_ehci {
	status = "okay";
};

&usb_host0_ohci {
	status = "okay";
};

/*
 * USB2 Host1: CH334H 4-port USB 2.0 hub (C276).
 *
 * Hardware (from carrier-board schematic):
 *   - CH334H is a 4-port USB 2.0 hub controller
 *   - VBUS 5V always-on (no enable GPIO)
 *   - Reset via NPOR_u (PMU power-on reset, auto-release — no GPIO)
 *   - USB2 D+/D− upstream port to SoC, 4× downstream D+/D−
 *
 * Downstream devices on CH334H hub:
 *   - FCU761K-L WiFi/BT module (Quectel, AIC8800DC chip, USB 2.0)
 *     WiFi: 2.4 GHz 1×1, USB 2.0 full-speed enumeration
 *     BT:   Bluetooth 4.2 BR/EDR, USB 2.0
 *     Driver: aic8800 (out-of-tree, CONFIG_AIC_WLAN_SUPPORT=m)
 *     Firmware: /lib/firmware/aic8800DC/ (pre-staged in rootfs overlay)
 *     No DTS node needed — USB auto-enumerates; no GPIO/power control.
 *
 * The CH334H is a standard USB hub; it auto-enumerates once the host
 * controller is active.  No board-specific DTS node needed for the hub
 * itself — only the host controller + PHY.
 */
&u2phy3 {
	status = "okay";
};

&u2phy3_host {
	status = "okay";
};

&usb_host1_ehci {
	status = "okay";
};

&usb_host1_ohci {
	status = "okay";
};

/*
 * SoC internal watchdog timer (Synopsys DW WDT at 0xfeaf0000).
 *
 * This is the RK3588 on-chip watchdog.  When it times out, it triggers
 * a SoC-level reset (equivalent to a warm reboot).  The timeout period
 * is configured by the driver (default 16 s in most Rockchip BSPs).
 *
 * Coexists with the external SGM820B watchdog below — the internal WDT
 * catches software hangs, while the external one provides an independent
 * hardware safety net that resets the entire board.
 */
&wdt {
	status = "okay";
};

/*
 * External hardware watchdog on carrier board: SGM820B-3.0 (U55).
 *   WDI  -> GPIO3_A6 (CPU kick signal, toggle algorithm)
 *   SET  -> VCC      (timeout ≈ 3.0 s)
 *   CWD  -> GND      (watchdog always enabled, cannot be disabled)
 *   WDO  -> system reset
 * The SoC internal &wdt above and this external watchdog coexist:
 * the internal one triggers a SoC-level reset, while the SGM820B is an
 * independent hardware safety mechanism that resets the whole board.
 * Requires CONFIG_GPIO_WATCHDOG=y in defconfig.
 */
/ {
	ext_wdt: watchdog-gpio {
		compatible = "linux,wdt-gpio";
		gpios = <&gpio3 RK_PA6 GPIO_ACTIVE_HIGH>;
		hw_algo = "toggle";
		hw_margin_ms = <3000>;
		always-running;
	};
};

/*
 * Fan support — two connectors on the carrier board.
 *
 * U9909 (B4B-XH-A, JST XH 4-pin, 2.5 mm pitch) — PWM speed-controlled fan:
 *   Pin 1: PWM speed control (5 V, level-shifted from SoC PWM2_M0 / GPIO0_C4
 *          via Q9501 2SK3018 N-MOSFET common-gate + R9905 10 kΩ pull-up to 5 V)
 *   Pin 2: NC (tachometer not wired)
 *   Pin 3: +12 V (always on, R9901 0 Ω to VDD_12V_MAIN, 100 nF + 10 µF decoupling)
 *   Pin 4: GND
 *
 * J31 (KF2510-3A, 3-pin, 2.54 mm pitch) — GPIO on/off fan:
 *   Pin 1: NC
 *   Pin 2: Switched +12 V (Q9502 CJ3401 P-MOSFET high-side switch)
 *   Pin 3: GND
 *   Control chain: SoC GPIO4_C3 (PWM4_M1, ball AF34) → R9912 10 kΩ →
 *     Q9503 MMBT3904 NPN → R9911 1 kΩ → Q9502 gate.
 *     GPIO HIGH → Q9503 ON → Q9502 gate LOW → Q9502 ON → 12 V output.
 *
 * Thermal integration: both fans are added as cooling devices to the
 * SoC thermal zone (soc_thermal).  When SoC temperature exceeds the
 * 85 °C target trip point, the thermal governor ramps up fan0 (PWM)
 * and turns on fan1 (GPIO), in addition to the existing CPU/GPU
 * frequency throttling.
 */
/ {
	fan0: pwm-fan {
		compatible = "pwm-fan";
		#cooling-cells = <2>;
		pwms = <&pwm2 0 40000 0>;	/* 25 kHz, standard PC fan PWM */
		cooling-levels = <0 80 120 160 200 255>;
	};

	fan1: gpio-fan {
		compatible = "gpio-fan";
		#cooling-cells = <2>;
		gpios = <&gpio4 RK_PC3 GPIO_ACTIVE_HIGH>;
		gpio-fan,speed-map = <0 0>, <5000 1>;
	};
};

&pwm2 {
	status = "okay";
	pinctrl-0 = <&pwm2m0_pins>;
};

&soc_thermal {
	cooling-maps {
		map4 {
			trip = <&target>;
			cooling-device = <&fan0 0 5>;
			contribution = <1024>;
		};
		map5 {
			trip = <&target>;
			cooling-device = <&fan1 0 1>;
			contribution = <1024>;
		};
	};
};

/*
 * SPI1 + XL2515 CAN controllers (carrier board, verified against netlist).
 *
 * Two MCP2515-compatible CAN controllers (U34=XL2515, U38=XL2515) on SPI1
 * (M2 mux). XL2515 is a register-compatible clone of MCP2515; the kernel
 * mcp251x driver has no separate compatible string for XL2515, so we use
 * "microchip,mcp2515".
 *   - SPI1 M2: CLK=F28/GPIO1_D2, MOSI=F27/GPIO1_D1, MISO=F26/GPIO1_D0
 *   - CS0=E28/GPIO1_D3 (U34), CS1=G26/GPIO1_D5 (U38)
 *   - Level shifter U17 (TXS0102) between SoC 1.8V and 3.3V domains
 *
 * CAN channel 0 (U34, XL2515):
 *   - SPI chip select: SPI1 CS0 (M2)
 *   - Interrupt: GPIO4_B5 (A/AJ26, CAN0_NINT, active-low)
 *   - Reset: GPIO3_D3 (A/AG24, CAN0_NRST) — RC power-on reset via R364/C201;
 *     gpio-hog output-high keeps controller out of reset after boot.
 *   - Crystal: Y7 = 16 MHz
 *   - Transceiver: U36 (ISO1050, galvanically isolated)
 *
 * CAN channel 1 (U38, XL2515):
 *   - SPI chip select: SPI1 CS1 (M2)
 *   - Interrupt: GPIO3_D2 (A/AG25, CAN1_NINT, active-low)
 *   - Reset: GPIO0_C7 (A/V31, CAN1_NRST) — RC power-on reset via R378/C208;
 *     gpio-hog output-high keeps controller out of reset after boot.
 *   - Crystal: Y8 = 16 MHz
 *   - Transceiver: U39 (ISO1050, galvanically isolated)
 *
 * The MCP251x driver performs a software reset via SPI (INSTRUCTION_RESET);
 * no reset-gpios DT property is needed. The external NRESET pins have RC
 * delay circuits and are held high by gpio-hog.
 */
&spi1 {
	pinctrl-0 = <&spi1m2_pins &spi1m2_cs0 &spi1m2_cs1>;
	status = "okay";

	mcp2515_0: can@0 {
		compatible = "microchip,mcp2515";
		reg = <0>;
		clocks = <&clk_16m_can>;
		interrupt-parent = <&gpio4>;
		interrupts = <RK_PB5 IRQ_TYPE_LEVEL_LOW>;
		pinctrl-names = "default";
		pinctrl-0 = <&can0_int>;
		status = "okay";
	};

	mcp2515_1: can@1 {
		compatible = "microchip,mcp2515";
		reg = <1>;
		clocks = <&clk_16m_can>;
		interrupt-parent = <&gpio3>;
		interrupts = <RK_PD2 IRQ_TYPE_LEVEL_LOW>;
		pinctrl-names = "default";
		pinctrl-0 = <&can1_int>;
		status = "okay";
	};
};

/* CAN controller reset GPIOs: hold high (deassert reset) at boot */
&gpio0 {
	can1-rst-hog {
		gpio-hog;
		gpios = <RK_PC7 GPIO_ACTIVE_HIGH>;
		output-high;
		line-name = "can1-rst";
	};
};

&gpio3 {
	can0-rst-hog {
		gpio-hog;
		gpios = <RK_PD3 GPIO_ACTIVE_HIGH>;
		output-high;
		line-name = "can0-rst";
	};
};

/*
 * Board-specific pinctrl overrides.
 *
 * USB Type-C0:
 *   usbc0_int: HUSB311 interrupt pin = GPIO4_B6, active-low, pull-up.
 *
 * XL9555 I/O expander:
 *   xl9555_int: interrupt pin = GPIO4_A0, active-low, pull-up (open-drain INT output).
 *
 * CAN controllers:
 *   can0_int: XL2515 U34 interrupt = GPIO4_B5, active-low, pull-up.
 *   can1_int: XL2515 U38 interrupt = GPIO3_D2, active-low, pull-up.
 *
 * NOTE: The board power button is PMIC_PWRONN (PMIC internal, no GPIO needed).
 */
&pinctrl {
	usb-typec {
		usbc0_int: usbc0-int {
			rockchip,pins = <4 RK_PB6 RK_FUNC_GPIO &pcfg_pull_up>;
		};
	};

	xl9555-int {
		xl9555_int: xl9555-int {
			rockchip,pins = <4 RK_PA0 RK_FUNC_GPIO &pcfg_pull_up>;
		};
	};

	hdmirx {
		hdmirx_det: hdmirx-det {
			rockchip,pins = <4 RK_PA1 RK_FUNC_GPIO &pcfg_pull_up>;
		};
	};

	fan1 {
		fan1_gpio: fan1-gpio {
			rockchip,pins = <4 RK_PC3 RK_FUNC_GPIO &pcfg_pull_none>;
		};
	};

	can0 {
		can0_int: can0-int {
			rockchip,pins = <4 RK_PB5 RK_FUNC_GPIO &pcfg_pull_up>;
		};
	};

	can1 {
		can1_int: can1-int {
			rockchip,pins = <3 RK_PD2 RK_FUNC_GPIO &pcfg_pull_up>;
		};
	};
};
